# APM32E103xx register map
File version: 1.0
CPU: CM3 r2p1, little endian, no MPU, no FPU, 4 interrupt priority bits
Registers are 32-bit, read-write, reset 0x0 unless marked. A register's access mark holds for its fields unless they carry their own. Offsets are from the block's base; [hi:lo] are bit positions; {n}, {i} and the like mark numbered series.

## USART1 — Universal synchronous asynchronous receiver transmitter
Base 0x40013800
Same registers: USART2 0x40004400, USART3 0x40004800
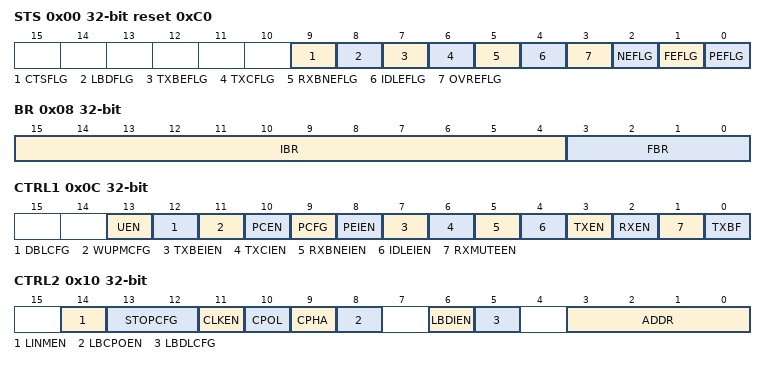
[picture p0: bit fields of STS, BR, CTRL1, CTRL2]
0x00 STS access per field reset 0xC0 — Status register
  [9] CTSFLG rw — CTS flag
  [8] LBDFLG rw — LIN break detection flag
  [7] TXBEFLG ro — Transmit data register empty
  [6] TXCFLG rw — Transmission complete
  [5] RXBNEFLG rw — Read data register not empty
  [4] IDLEFLG ro — IDLE line detected
  [3] OVREFLG ro — Overrun error
  [2] NEFLG ro — Noise error flag
  [1] FEFLG ro — Framing error
  [0] PEFLG ro — Parity error
0x04 DATA — TX Buffer Data Register
  [8:0] DATA — Data value
0x08 BR — Baud rate register
  [15:4] IBR — Integer of USARTDIV
  [3:0] FBR — Fraction of USARTDIV
0x0C CTRL1 — Control register 1
  [13] UEN — USART enable
  [12] DBLCFG — Word length
  [11] WUPMCFG — Wakeup method
  [10] PCEN — Parity control enable
  [9] PCFG — Parity selection
  [8] PEIEN — PE interrupt enable
  [7] TXBEIEN — TXBE interrupt enable
  [6] TXCIEN — Transmission complete interrupt enable
  [5] RXBNEIEN — RXBNE interrupt enable
  [4] IDLEIEN — IDLE interrupt enable
  [3] TXEN — Transmitter enable
  [2] RXEN — Receiver enable
  [1] RXMUTEEN — Receiver wakeup
  [0] TXBF — Send break
0x10 CTRL2 — Control register 2
  [14] LINMEN — LIN mode enable
  [13:12] STOPCFG — STOP bits
  [11] CLKEN — Clock enable
  [10] CPOL — Clock polarity
  [9] CPHA — Clock phase
  [8] LBCPOEN — Last bit clock pulse
  [6] LBDIEN — LIN break detection interrupt enable
  [5] LBDLCFG — lin break detection length
  [3:0] ADDR — Address of the USART node
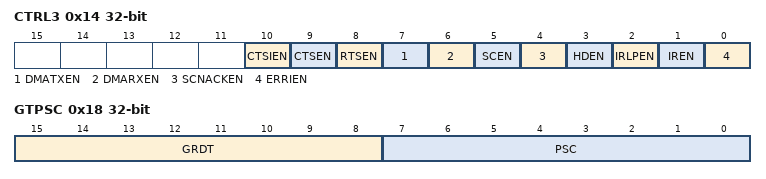
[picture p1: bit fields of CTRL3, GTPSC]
0x14 CTRL3 — Control register 3
  [10] CTSIEN — CTS interrupt enable
  [9] CTSEN — CTS enable
  [8] RTSEN — RTS enable
  [7] DMATXEN — DMA enable transmitter
  [6] DMARXEN — DMA enable receiver
  [5] SCEN — Smartcard mode enable
  [4] SCNACKEN — Smartcard NACK enable
  [3] HDEN — Half-duplex selection
  [2] IRLPEN — IrDA low-power
  [1] IREN — IrDA mode enable
  [0] ERRIEN — Error interrupt enable
0x18 GTPSC — Guard time and divider number register
  [15:8] GRDT — Guard time value
  [7:0] PSC — Prescaler value

## UART5
Base 0x40005000
Registers as USART1; these are added or differ:
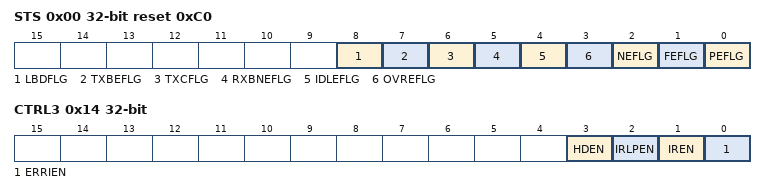
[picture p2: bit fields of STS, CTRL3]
0x00 STS access per field reset 0xC0 — Status register
  [8] LBDFLG rw — LIN break detection flag
  [7] TXBEFLG ro — Transmit data register empty
  [6] TXCFLG rw — Transmission complete
  [5] RXBNEFLG rw — Read data register not empty
  [4] IDLEFLG ro — IDLE line detected
  [3] OVREFLG ro — Overrun error
  [2] NEFLG ro — Noise error flag
  [1] FEFLG ro — Framing error
  [0] PEFLG ro — Parity error
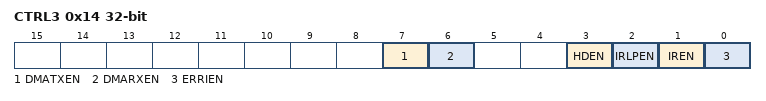
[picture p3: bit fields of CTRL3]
0x14 CTRL3 — Control register 3
  [3] HDEN — Half-duplex selection
  [2] IRLPEN — IrDA low-power
  [1] IREN — IrDA mode enable
  [0] ERRIEN — Error interrupt enable

## UART4
Base 0x40004C00
Registers as UART5; these are added or differ:
0x14 CTRL3 — Control register 3
  [7] DMATXEN — DMA enable transmitter
  [6] DMARXEN — DMA enable receiver
  [3] HDEN — Half-duplex selection
  [2] IRLPEN — IrDA low-power
  [1] IREN — IrDA mode enable
  [0] ERRIEN — Error interrupt enable

## GPIOA — General purpose I/O
Base 0x40010800
Same registers: GPIOB 0x40010C00, GPIOC 0x40011000, GPIOD 0x40011400, GPIOE 0x40011800, GPIOF 0x40011C00, GPIOG 0x40012000
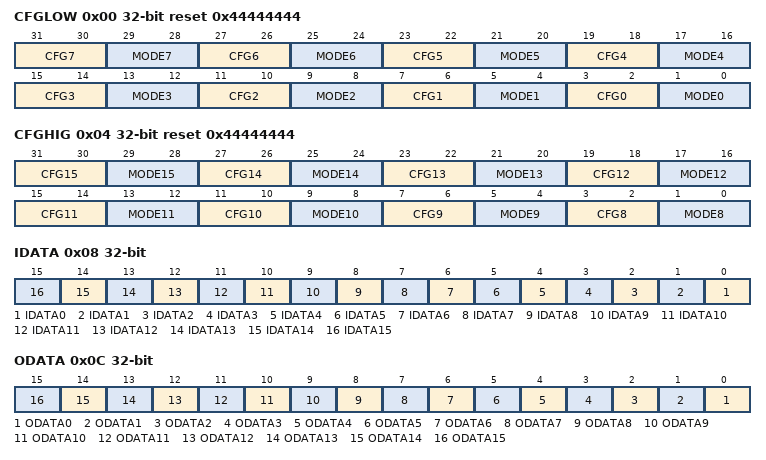
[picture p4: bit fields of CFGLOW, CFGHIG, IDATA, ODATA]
0x00 CFGLOW reset 0x44444444 — Port configuration register 0 (GPIOn_CFGLOW)
  [31:30] CFG7 — Port n.7 configuration bits
  [29:28] MODE7 — Port n.7 mode bits
  [27:26] CFG6 — Port n.6 configuration bits
  [25:24] MODE6 — Port n.6 mode bits
  [23:22] CFG5 — Port n.5 configuration bits
  [21:20] MODE5 — Port n.5 mode bits
  [19:18] CFG4 — Port n.4 configuration bits
  [17:16] MODE4 — Port n.4 mode bits
  [15:14] CFG3 — Port n.3 configuration bits
  [13:12] MODE3 — Port n.3 mode bits
  [11:10] CFG2 — Port n.2 configuration bits
  [9:8] MODE2 — Port n.2 mode bits
  [7:6] CFG1 — Port n.1 configuration bits
  [5:4] MODE1 — Port n.1 mode bits
  [3:2] CFG0 — Port n.0 configuration bits
  [1:0] MODE0 — Port n.0 mode bits
0x04 CFGHIG reset 0x44444444 — Port configuration register 1 (GPIOn_CFGHIG)
  [31:30] CFG15 — Port n.15 configuration bits
  [29:28] MODE15 — Port n.15 mode bits
  [27:26] CFG14 — Port n.14 configuration bits
  [25:24] MODE14 — Port n.14 mode bits
  [23:22] CFG13 — Port n.13 configuration bits
  [21:20] MODE13 — Port n.13 mode bits
  [19:18] CFG12 — Port n.12 configuration bits
  [17:16] MODE12 — Port n.12 mode bits
  [15:14] CFG11 — Port n.11 configuration bits
  [13:12] MODE11 — Port n.11 mode bits
  [11:10] CFG10 — Port n.10 configuration bits
  [9:8] MODE10 — Port n.10 mode bits
  [7:6] CFG9 — Port n.9 configuration bits
  [5:4] MODE9 — Port n.9 mode bits
  [3:2] CFG8 — Port n.8 configuration bits
  [1:0] MODE8 — Port n.8 mode bits
0x08 IDATA ro — Port input data register (GPIOn_IDATA)
  [n] IDATA{n} (n=0..15) — Port input data
0x0C ODATA — Port output data register (GPIOn_ODATA)
  [n] ODATA{n} (n=0..15) — Port output data
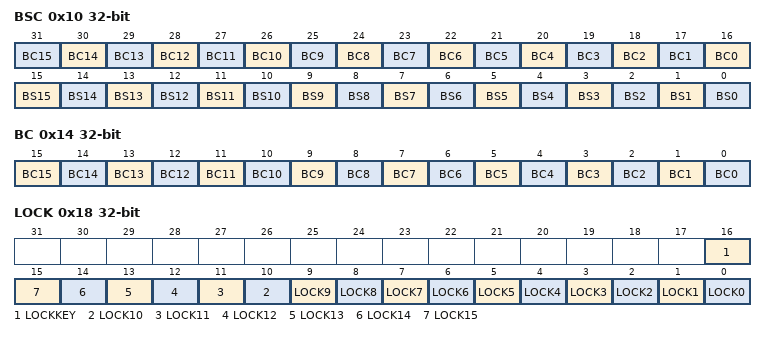
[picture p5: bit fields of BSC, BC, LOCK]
0x10 BSC wo — Port bit set/reset register (GPIOn_BSC)
  [n+16] BC{n} (n=0..15) — Clear bit {n}
  [n] BS{n} (n=3..15) — Set bit {n}
  [2] BS2 — Set bit 1
  [1] BS1 — Set bit 1
  [0] BS0 — Set bit 0
0x14 BC wo — Port bit clear register (GPIOn_BC)
  [n] BC{n} (n=3..15) — Clear bit {n}
  [2] BC2 — Clear bit 1
  [1] BC1 — Clear bit 1
  [0] BC0 — Clear bit 0
0x18 LOCK — Port configuration lock register (GPIOn_LOCK)
  [16] LOCKKEY
  [n] LOCK{n} (n=0..15) — Port A Lock bit {n}
